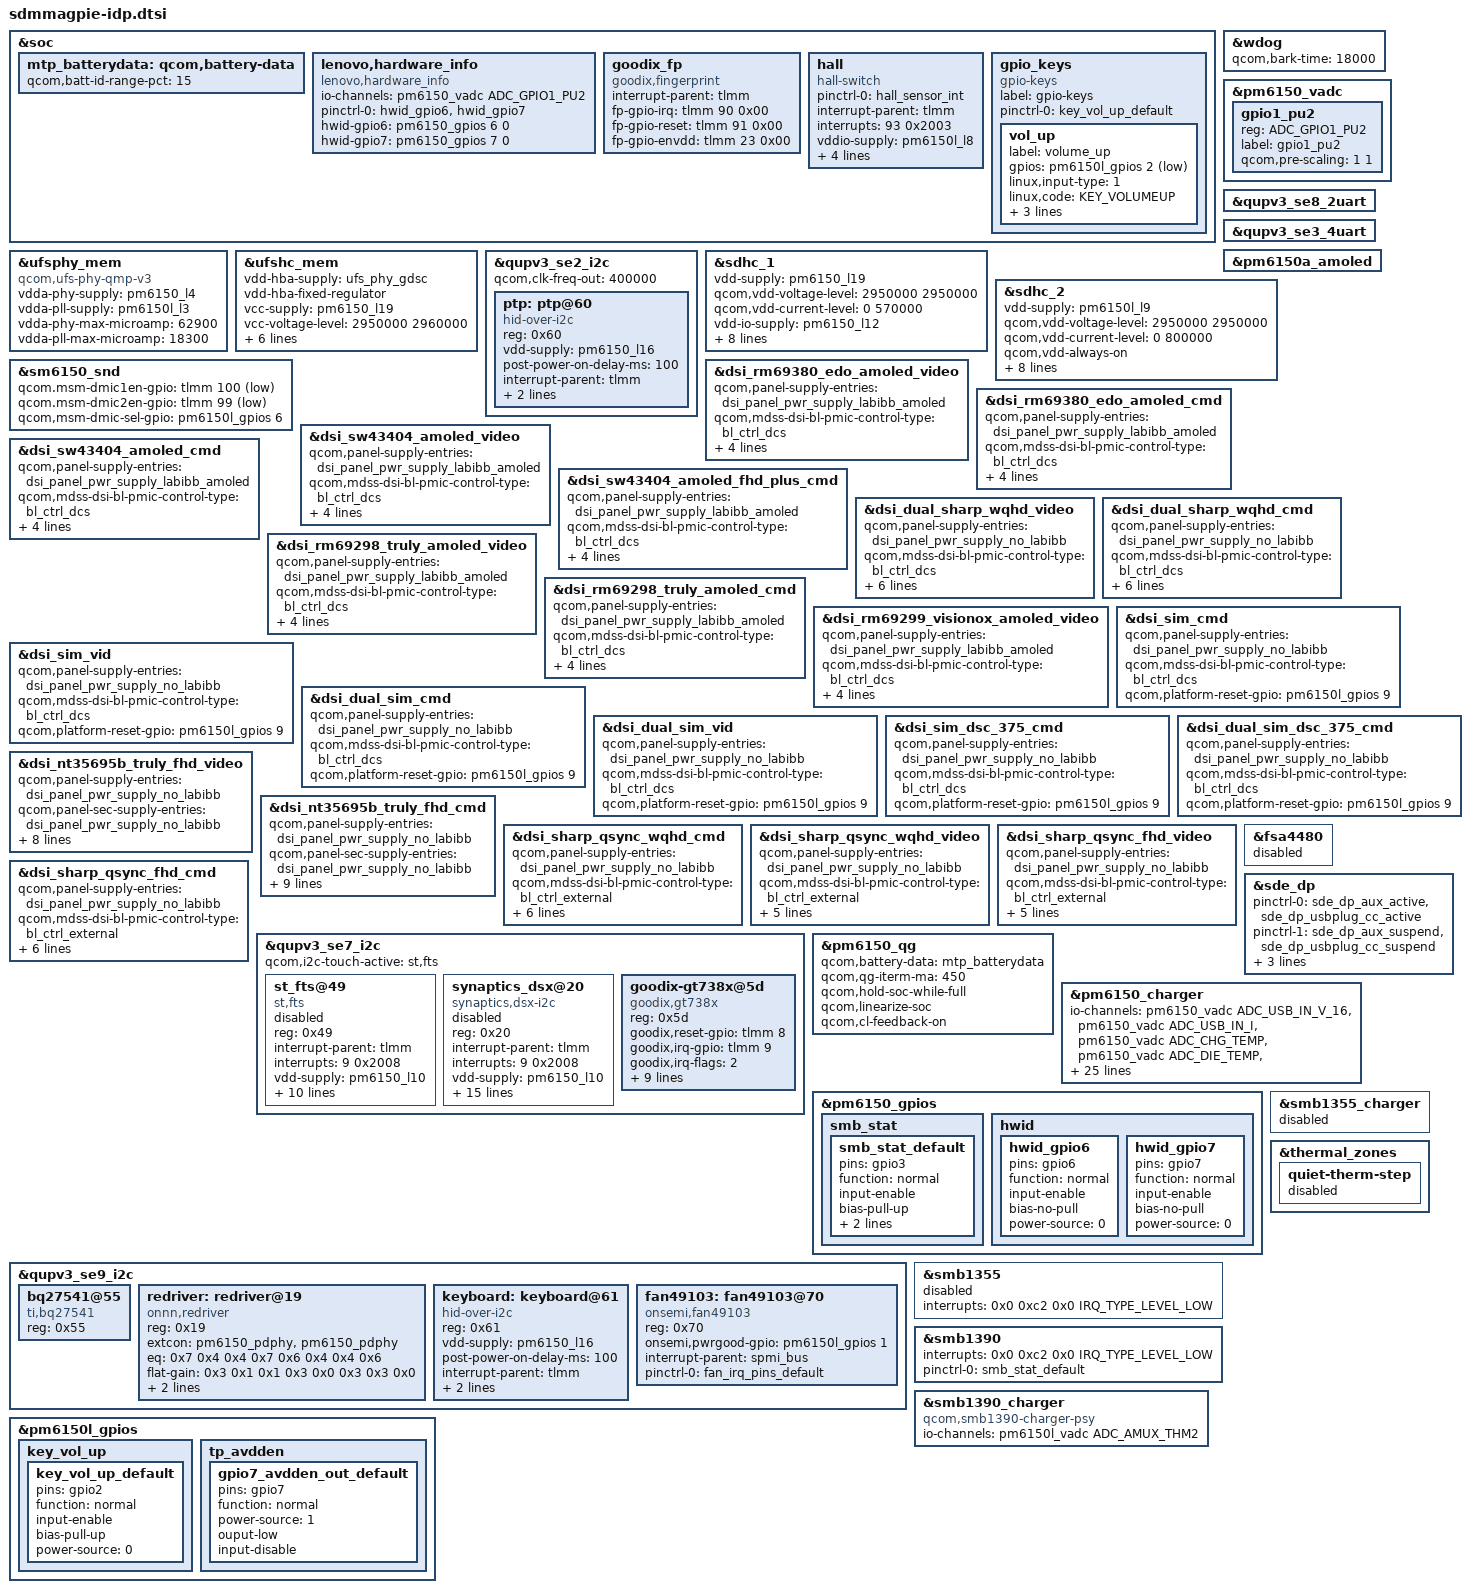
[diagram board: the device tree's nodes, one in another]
/* Copyright (c) 2018-2019, The Linux Foundation. All rights reserved.
 *
 * This program is free software; you can redistribute it and/or modify
 * it under the terms of the GNU General Public License version 2 and
 * only version 2 as published by the Free Software Foundation.
 *
 * This program is distributed in the hope that it will be useful,
 * but WITHOUT ANY WARRANTY; without even the implied warranty of
 * MERCHANTABILITY or FITNESS FOR A PARTICULAR PURPOSE.  See the
 * GNU General Public License for more details.
 */
#include "sdmmagpie-thermal-overlay.dtsi"

#include <dt-bindings/gpio/gpio.h>
#include <dt-bindings/pinctrl/qcom,pmic-gpio.h>
#include <dt-bindings/iio/qcom,spmi-vadc.h>
#include <dt-bindings/input/input.h>
#include "sdmmagpie-sde-display.dtsi"
#include "sdmmagpie-camera-sensor-idp.dtsi"

&soc {
	mtp_batterydata: qcom,battery-data {
		qcom,batt-id-range-pct = <15>;
		#include "qg-batterydata-alium-3600mah.dtsi"
		#include "qg-batterydata-mlp466076-3200mah.dtsi"
	};
	lenovo,hardware_info {
		compatible = "lenovo,hardware_info";
		io-channels = <&pm6150_vadc ADC_GPIO1_PU2>;
		io-channel-names = "hwid_gpio1";
		pinctrl-names = "default";
		pinctrl-0 = <&hwid_gpio6 &hwid_gpio7>;
		hwid-gpio6 = <&pm6150_gpios 6 0>;
		hwid-gpio7 = <&pm6150_gpios 7 0>;
		status = "ok";
	};
	goodix_fp {
			compatible = "goodix,fingerprint";
			interrupt-parent = <&tlmm>;
			fp-gpio-irq = <&tlmm 90 0x00>;
			fp-gpio-reset = <&tlmm 91 0x00>;
			fp-gpio-envdd = <&tlmm 23 0x00>;
			status = "okay";
	};
	hall {
		compatible = "hall-switch";
		pinctrl-names = "default";
		pinctrl-0 = <&hall_sensor_int>;
		interrupt-parent = <&tlmm>;
		interrupts = <93 0x2003>;
		vddio-supply = <&pm6150l_l8>;
		linux,gpio-int = <&tlmm 93 0x1>;
		linux,wakeup;
		linux,min-uv = <1650000>;
		linux,max-uv = <3300000>;
	};
};
&wdog {
	qcom,bark-time = <18000>;
};

&pm6150_vadc {
	gpio1_pu2 {
		reg = <ADC_GPIO1_PU2>;
		label = "gpio1_pu2";
		qcom,pre-scaling = <1 1>;
	};
};

&qupv3_se8_2uart {
	status = "ok";
};

&qupv3_se3_4uart {
	status = "ok";
};

&pm6150a_amoled {
	status = "ok";
};

&ufsphy_mem {
	compatible = "qcom,ufs-phy-qmp-v3";

	vdda-phy-supply = <&pm6150_l4>; /* 0.88v */
	vdda-pll-supply = <&pm6150l_l3>; /* 1.2v */
	vdda-phy-max-microamp = <62900>;
	vdda-pll-max-microamp = <18300>;

	status = "ok";
};

&ufshc_mem {
	vdd-hba-supply = <&ufs_phy_gdsc>;
	vdd-hba-fixed-regulator;
	vcc-supply = <&pm6150_l19>;
	vcc-voltage-level = <2950000 2960000>;
	vccq2-supply = <&pm6150_l12>;
	vccq2-voltage-level = <1750000 1950000>;
	vcc-max-microamp = <600000>;
	vccq2-max-microamp = <600000>;

	qcom,vddp-ref-clk-supply = <&pm6150l_l3>;
	qcom,vddp-ref-clk-max-microamp = <100>;

	status = "ok";
};

&qupv3_se2_i2c {
	status = "ok";
	qcom,clk-freq-out = <400000>;
	 ptp: ptp@60{
		       compatible = "hid-over-i2c";
		       reg = <0x60>;
		    /* pinctrl-names = "default";
		       pinctrl-0 = <&cpu1_dig_irq_l &cpu1_dig_pdct_l>;*/
	           vdd-supply = <&pm6150_l16>;
	           post-power-on-delay-ms = <100>;
	           interrupt-parent = <&tlmm>;
	           interrupts = <4 0x2002>;
	           hid-descr-addr = <0x0001>;
		    };
	/*
	nq@28 {
		compatible = "qcom,nq-nci";
		reg = <0x28>;
		qcom,nq-irq = <&tlmm 37 0x00>;
		qcom,nq-ven = <&tlmm 12 0x00>;
		qcom,nq-firm = <&tlmm 36 0x00>;
		qcom,nq-clkreq = <&tlmm 31 0x00>;
		qcom,nq-esepwr = <&tlmm 94 0x00>;
		interrupt-parent = <&tlmm>;
		interrupts = <37 0>;
		interrupt-names = "nfc_irq";
		pinctrl-names = "nfc_active", "nfc_suspend";
		pinctrl-0 = <&nfc_int_active &nfc_enable_active
				&nfc_clk_req_active>;
		pinctrl-1 = <&nfc_int_suspend &nfc_enable_suspend
				&nfc_clk_req_suspend>;
	};*/
};

&sdhc_1 {
	vdd-supply = <&pm6150_l19>;
	qcom,vdd-voltage-level = <2950000 2950000>;
	qcom,vdd-current-level = <0 570000>;

	vdd-io-supply = <&pm6150_l12>;
	qcom,vdd-io-always-on;
	qcom,vdd-io-lpm-sup;
	qcom,vdd-io-voltage-level = <1800000 1800000>;
	qcom,vdd-io-current-level = <0 325000>;

	pinctrl-names = "active", "sleep";
	pinctrl-0 = <&sdc1_clk_on &sdc1_cmd_on &sdc1_data_on &sdc1_rclk_on>;
	pinctrl-1 = <&sdc1_clk_off &sdc1_cmd_off &sdc1_data_off &sdc1_rclk_off>;

	status = "ok";
};

&sdhc_2 {
	vdd-supply = <&pm6150l_l9>;
	qcom,vdd-voltage-level = <2950000 2950000>;
	qcom,vdd-current-level = <0 800000>;
	qcom,vdd-always-on;

	vdd-io-supply = <&pm6150l_l6>;
	qcom,vdd-io-voltage-level = <1800000 2950000>;
	qcom,vdd-io-current-level = <0 22000>;

	pinctrl-names = "active", "sleep";
	pinctrl-0 = <&sdc2_clk_on  &sdc2_cmd_on &sdc2_data_on &sdc2_cd_on>;
	pinctrl-1 = <&sdc2_clk_off &sdc2_cmd_off &sdc2_data_off &sdc2_cd_off>;

	cd-gpios = <&tlmm 69 GPIO_ACTIVE_HIGH>;

	status = "ok";
};

&sm6150_snd {
	qcom.msm-dmic1en-gpio=<&tlmm 100 1>;
	qcom.msm-dmic2en-gpio=<&tlmm 99 1>;
	qcom,msm-dmic-sel-gpio = <&pm6150l_gpios 6 0>;
};

&dsi_rm69380_edo_amoled_video {
	qcom,panel-supply-entries = <&dsi_panel_pwr_supply_labibb_amoled>;
	qcom,mdss-dsi-bl-pmic-control-type = "bl_ctrl_dcs";
	qcom,mdss-dsi-bl-min-level = <1>;
	qcom,mdss-dsi-bl-max-level = <2047>;	// 11bit
	qcom,platform-te-gpio = <&tlmm 10 0>;
	qcom,platform-reset-gpio = <&pm6150l_gpios 9 0>;
};

&dsi_rm69380_edo_amoled_cmd {
	qcom,panel-supply-entries = <&dsi_panel_pwr_supply_labibb_amoled>;
	qcom,mdss-dsi-bl-pmic-control-type = "bl_ctrl_dcs";
	qcom,mdss-dsi-bl-min-level = <1>;
	qcom,mdss-dsi-bl-max-level = <2047>;	// 11bit
	qcom,platform-te-gpio = <&tlmm 10 0>;
	qcom,platform-reset-gpio = <&pm6150l_gpios 9 0>;
};
&dsi_sw43404_amoled_video {
	qcom,panel-supply-entries = <&dsi_panel_pwr_supply_labibb_amoled>;
	qcom,mdss-dsi-bl-pmic-control-type = "bl_ctrl_dcs";
	qcom,mdss-dsi-bl-min-level = <1>;
	qcom,mdss-dsi-bl-max-level = <1023>;
	qcom,platform-te-gpio = <&tlmm 10 0>;
	qcom,platform-reset-gpio = <&pm6150l_gpios 9 0>;
};

&dsi_sw43404_amoled_cmd {
	qcom,panel-supply-entries = <&dsi_panel_pwr_supply_labibb_amoled>;
	qcom,mdss-dsi-bl-pmic-control-type = "bl_ctrl_dcs";
	qcom,mdss-dsi-bl-min-level = <1>;
	qcom,mdss-dsi-bl-max-level = <1023>;
	qcom,platform-te-gpio = <&tlmm 10 0>;
	qcom,platform-reset-gpio = <&pm6150l_gpios 9 0>;
};

&dsi_sw43404_amoled_fhd_plus_cmd {
	qcom,panel-supply-entries = <&dsi_panel_pwr_supply_labibb_amoled>;
	qcom,mdss-dsi-bl-pmic-control-type = "bl_ctrl_dcs";
	qcom,mdss-dsi-bl-min-level = <1>;
	qcom,mdss-dsi-bl-max-level = <1023>;
	qcom,platform-te-gpio = <&tlmm 10 0>;
	qcom,platform-reset-gpio = <&pm6150l_gpios 9 0>;
};

&dsi_dual_sharp_wqhd_video {
	qcom,panel-supply-entries = <&dsi_panel_pwr_supply_no_labibb>;
	qcom,mdss-dsi-bl-pmic-control-type = "bl_ctrl_dcs";
	qcom,mdss-dsi-bl-min-level = <1>;
	qcom,mdss-dsi-bl-max-level = <4095>;
	qcom,platform-te-gpio = <&tlmm 10 0>;
	qcom,platform-reset-gpio = <&pm6150l_gpios 9 0>;
	qcom,platform-en-gpio = <&pm6150l_gpios 4 0>;
	qcom,platform-bklight-en-gpio = <&pm6150l_gpios 5 0>;
};

&dsi_dual_sharp_wqhd_cmd {
	qcom,panel-supply-entries = <&dsi_panel_pwr_supply_no_labibb>;
	qcom,mdss-dsi-bl-pmic-control-type = "bl_ctrl_dcs";
	qcom,mdss-dsi-bl-min-level = <1>;
	qcom,mdss-dsi-bl-max-level = <4095>;
	qcom,platform-te-gpio = <&tlmm 10 0>;
	qcom,platform-reset-gpio = <&pm6150l_gpios 9 0>;
	qcom,platform-en-gpio = <&pm6150l_gpios 4 0>;
	qcom,platform-bklight-en-gpio = <&pm6150l_gpios 5 0>;
};

&dsi_rm69298_truly_amoled_video {
	qcom,panel-supply-entries = <&dsi_panel_pwr_supply_labibb_amoled>;
	qcom,mdss-dsi-bl-pmic-control-type = "bl_ctrl_dcs";
	qcom,mdss-dsi-bl-min-level = <1>;
	qcom,mdss-dsi-bl-max-level = <255>;
	qcom,platform-te-gpio = <&tlmm 10 0>;
	qcom,platform-reset-gpio = <&pm6150l_gpios 9 0>;
};

&dsi_rm69298_truly_amoled_cmd {
	qcom,panel-supply-entries = <&dsi_panel_pwr_supply_labibb_amoled>;
	qcom,mdss-dsi-bl-pmic-control-type = "bl_ctrl_dcs";
	qcom,mdss-dsi-bl-min-level = <1>;
	qcom,mdss-dsi-bl-max-level = <255>;
	qcom,platform-te-gpio = <&tlmm 10 0>;
	qcom,platform-reset-gpio = <&pm6150l_gpios 9 0>;
};

&dsi_rm69299_visionox_amoled_video {
	qcom,panel-supply-entries = <&dsi_panel_pwr_supply_labibb_amoled>;
	qcom,mdss-dsi-bl-pmic-control-type = "bl_ctrl_dcs";
	qcom,mdss-dsi-bl-min-level = <1>;
	qcom,mdss-dsi-bl-max-level = <255>;
	qcom,platform-te-gpio = <&tlmm 10 0>;
	qcom,platform-reset-gpio = <&pm6150l_gpios 9 0>;
};

&dsi_sim_cmd {
	qcom,panel-supply-entries = <&dsi_panel_pwr_supply_no_labibb>;
	qcom,mdss-dsi-bl-pmic-control-type = "bl_ctrl_dcs";
	qcom,platform-reset-gpio = <&pm6150l_gpios 9 0>;
};

&dsi_sim_vid {
	qcom,panel-supply-entries = <&dsi_panel_pwr_supply_no_labibb>;
	qcom,mdss-dsi-bl-pmic-control-type = "bl_ctrl_dcs";
	qcom,platform-reset-gpio = <&pm6150l_gpios 9 0>;
};

&dsi_dual_sim_cmd {
	qcom,panel-supply-entries = <&dsi_panel_pwr_supply_no_labibb>;
	qcom,mdss-dsi-bl-pmic-control-type = "bl_ctrl_dcs";
	qcom,platform-reset-gpio = <&pm6150l_gpios 9 0>;
};

&dsi_dual_sim_vid {
	qcom,panel-supply-entries = <&dsi_panel_pwr_supply_no_labibb>;
	qcom,mdss-dsi-bl-pmic-control-type = "bl_ctrl_dcs";
	qcom,platform-reset-gpio = <&pm6150l_gpios 9 0>;
};

&dsi_sim_dsc_375_cmd {
	qcom,panel-supply-entries = <&dsi_panel_pwr_supply_no_labibb>;
	qcom,mdss-dsi-bl-pmic-control-type = "bl_ctrl_dcs";
	qcom,platform-reset-gpio = <&pm6150l_gpios 9 0>;
};

&dsi_dual_sim_dsc_375_cmd {
	qcom,panel-supply-entries = <&dsi_panel_pwr_supply_no_labibb>;
	qcom,mdss-dsi-bl-pmic-control-type = "bl_ctrl_dcs";
	qcom,platform-reset-gpio = <&pm6150l_gpios 9 0>;
};

&dsi_nt35695b_truly_fhd_video {
	qcom,panel-supply-entries = <&dsi_panel_pwr_supply_no_labibb>;
	qcom,panel-sec-supply-entries = <&dsi_panel_pwr_supply_no_labibb>;
	qcom,mdss-dsi-bl-pmic-control-type = "bl_ctrl_dcs";
	qcom,mdss-dsi-sec-bl-pmic-control-type = "bl_ctrl_dcs";
	qcom,platform-reset-gpio = <&pm6150l_gpios 11 0>;
	qcom,platform-sec-reset-gpio = <&pm6150l_gpios 11 0>;
	qcom,platform-en-gpio = <&pm6150l_gpios 4 0>;
	qcom,platform-bklight-en-gpio = <&pm6150l_gpios 5 0>;
};

&dsi_nt35695b_truly_fhd_cmd {
	qcom,panel-supply-entries = <&dsi_panel_pwr_supply_no_labibb>;
	qcom,panel-sec-supply-entries = <&dsi_panel_pwr_supply_no_labibb>;
	qcom,mdss-dsi-bl-pmic-control-type = "bl_ctrl_dcs";
	qcom,mdss-dsi-sec-bl-pmic-control-type = "bl_ctrl_dcs";
	qcom,platform-reset-gpio = <&pm6150l_gpios 11 0>;
	qcom,platform-sec-reset-gpio = <&pm6150l_gpios 11 0>;
	qcom,platform-en-gpio = <&pm6150l_gpios 4 0>;
	qcom,platform-bklight-en-gpio = <&pm6150l_gpios 5 0>;
	qcom,platform-te-gpio = <&tlmm 11 0>;
};

&dsi_sharp_qsync_wqhd_cmd {
	qcom,panel-supply-entries = <&dsi_panel_pwr_supply_no_labibb>;
	qcom,mdss-dsi-bl-pmic-control-type = "bl_ctrl_external";
	qcom,mdss-dsi-bl-min-level = <1>;
	qcom,mdss-dsi-bl-max-level = <4095>;
	qcom,platform-te-gpio = <&tlmm 10 0>;
	qcom,platform-reset-gpio = <&pm6150l_gpios 9 0>;
	qcom,platform-en-gpio = <&pm6150l_gpios 4 0>;
	qcom,platform-bklight-en-gpio = <&pm6150l_gpios 5 0>;
};

&dsi_sharp_qsync_wqhd_video {
	qcom,panel-supply-entries = <&dsi_panel_pwr_supply_no_labibb>;
	qcom,mdss-dsi-bl-pmic-control-type = "bl_ctrl_external";
	qcom,mdss-dsi-bl-min-level = <1>;
	qcom,mdss-dsi-bl-max-level = <4095>;
	qcom,platform-reset-gpio = <&pm6150l_gpios 9 0>;
	qcom,platform-en-gpio = <&pm6150l_gpios 4 0>;
	qcom,platform-bklight-en-gpio = <&pm6150l_gpios 5 0>;
};

&dsi_sharp_qsync_fhd_video {
	qcom,panel-supply-entries = <&dsi_panel_pwr_supply_no_labibb>;
	qcom,mdss-dsi-bl-pmic-control-type = "bl_ctrl_external";
	qcom,mdss-dsi-bl-min-level = <1>;
	qcom,mdss-dsi-bl-max-level = <4095>;
	qcom,platform-reset-gpio = <&pm6150l_gpios 9 0>;
	qcom,platform-en-gpio = <&pm6150l_gpios 4 0>;
	qcom,platform-bklight-en-gpio = <&pm6150l_gpios 5 0>;
};

&dsi_sharp_qsync_fhd_cmd {
	qcom,panel-supply-entries = <&dsi_panel_pwr_supply_no_labibb>;
	qcom,mdss-dsi-bl-pmic-control-type = "bl_ctrl_external";
	qcom,mdss-dsi-bl-min-level = <1>;
	qcom,mdss-dsi-bl-max-level = <4095>;
	qcom,platform-te-gpio = <&tlmm 10 0>;
	qcom,platform-reset-gpio = <&pm6150l_gpios 9 0>;
	qcom,platform-en-gpio = <&pm6150l_gpios 4 0>;
	qcom,platform-bklight-en-gpio = <&pm6150l_gpios 5 0>;
};
&fsa4480 {
	status = "disabled";
};
&sde_dp {
/*  	for gpio switch*/

	pinctrl-names = "mdss_dp_active", "mdss_dp_sleep";
	pinctrl-0 = <&sde_dp_aux_active &sde_dp_usbplug_cc_active>;
	pinctrl-1 = <&sde_dp_aux_suspend &sde_dp_usbplug_cc_suspend>;
	qcom,aux-en-gpio = <&tlmm 25 0>;
	qcom,aux-sel-gpio = <&tlmm 33 0>;
	qcom,dp-gpio-aux-switch;

	//qcom,dp-aux-switch = <&redriver>;
};

&qupv3_se7_i2c {
	qcom,i2c-touch-active="st,fts";
	status = "ok";

	st_fts@49 {
		compatible = "st,fts";
		reg = <0x49>;
		interrupt-parent = <&tlmm>;
		interrupts = <9 0x2008>;
		vdd-supply = <&pm6150_l10>;
		avdd-supply = <&pm6150l_l7>;
		pinctrl-names = "pmx_ts_active", "pmx_ts_suspend",
					"pmx_ts_release";
		pinctrl-0 = <&ts_active>;
		pinctrl-1 = <&ts_int_suspend &ts_reset_suspend>;
		pinctrl-2 = <&ts_release>;
		st,irq-gpio = <&tlmm 9 0x2008>;
		st,reset-gpio = <&tlmm 8 0x00>;
		st,regulator_dvdd = "vdd";
		st,regulator_avdd = "avdd";
		st,x-flip;
		st,y-flip;
		status = "disabled";
	};

	synaptics_dsx@20 {
		compatible = "synaptics,dsx-i2c";
		reg = <0x20>;
		interrupt-parent = <&tlmm>;
		interrupts = <9 0x2008>;
		vdd-supply = <&pm6150_l10>;
		avdd-supply = <&pm6150l_l7>;
		pinctrl-names = "pmx_ts_active","pmx_ts_suspend",
					"pmx_ts_release";
		pinctrl-0 = <&ts_active>;
		pinctrl-1 = <&ts_int_suspend &ts_reset_suspend>;
		pinctrl-2 = <&ts_release>;
		synaptics,pwr-reg-name = "avdd";
		synaptics,bus-reg-name = "vdd";
		synaptics,ub-i2c-addr = <0x20>;
		synaptics,max-y-for-2d = <2159>;
		synaptics,irq-gpio = <&tlmm 9 0x2008>;
		synaptics,reset-gpio = <&tlmm 8 0x0>;
		synaptics,irq-on-state = <0>;
		synaptics,power-delay-ms = <200>;
		synaptics,reset-delay-ms = <200>;
		synaptics,reset-on-state = <0>;
		synaptics,reset-active-ms = <20>;
		status = "disabled";
	};
	goodix-gt738x@5d {
		compatible = "goodix,gt738x";
		reg = <0x5d>;
		goodix,reset-gpio = <&tlmm 8 0x0>;
		goodix,irq-gpio = <&tlmm 9 0x2008>;
		goodix,irq-flags = <2>; /* 1:trigger rising, 2:trigger falling;*/
		goodix,panel-max-x = <2560>;
		goodix,panel-max-y = <1600>;
		goodix,panel-max-w = <2368>;
		goodix,avdd-name ="avdd";
		goodix,avdd-en-gpio =<&pm6150l_gpios 7 0>;
		avdd-supply = <&pm6150l_l7>;
		pinctrl-names = "pmx_ts_active", "pmx_ts_suspend", "pmx_ts_release","avddengpio";
		pinctrl-0 = <&ts_active &gpio7_avdden_out_default>;
		pinctrl-1 = <&ts_int_suspend &ts_reset_suspend>;
		pinctrl-2 = <&ts_release>;
	};
};

&pm6150_qg {
	qcom,battery-data = <&mtp_batterydata>;
	qcom,qg-iterm-ma = <450>;
	qcom,hold-soc-while-full;
	qcom,linearize-soc;
	qcom,cl-feedback-on;
};

&pm6150_charger {
	io-channels = <&pm6150_vadc ADC_USB_IN_V_16>,
		      <&pm6150_vadc ADC_USB_IN_I>,
		      <&pm6150_vadc ADC_CHG_TEMP>,
		      <&pm6150_vadc ADC_DIE_TEMP>,
		      <&pm6150l_vadc ADC_AMUX_THM1_PU2>,
		      <&pm6150_vadc ADC_SBUx>,
		      <&pm6150_vadc ADC_VPH_PWR>;
	io-channel-names = "usb_in_voltage",
			   "usb_in_current",
			   "chg_temp",
			   "die_temp",
			   "conn_temp",
			   "sbux_res",
			   "vph_voltage";
	qcom,battery-data = <&mtp_batterydata>;
	/*qcom,auto-recharge-soc = <95>;*/
	qcom,auto-recharge-vbat-mv = <4330>;
	#qcom,step-charging-enable;
	qcom,sw-jeita-enable;
	#qcom,fcc-stepping-enable;
	#qcom,suspend-input-on-debug-batt;
	qcom,sec-charger-config = <1>;
	qcom,thermal-mitigation = <4200000 3500000 3000000
			2500000 2000000 1500000 1000000 500000>;
	dpdm-supply = <&qusb_phy0>;
	qcom,charger-temp-max = <800>;
	qcom,smb-temp-max = <800>;
	qcom,chg-term-src = <1>;
	qcom,chg-term-current-ma = <(-400)>;
	qcom,usb-icl-ua = <2000000>;
	qcom,float-option = <2>;
	qcom,boost_en=<&pm6150l_gpios 11 0>;
	pinctrl-names = "default";
	pinctrl-0 = <&pogo_gpio>;
	qcom,pogo_det-gpio=<&tlmm 94 0>;
	qcom,typec_det-gpio=<&tlmm 66 0>;
	qcom,pogo_en-gpio=<&tlmm 65 0>;
	qcom,typec_en-gpio=<&tlmm 74 0>;
};

&pm6150_gpios {
	smb_stat {
		smb_stat_default: smb_stat_default {
			pins = "gpio3";
			function = "normal";
			input-enable;
			bias-pull-up;
			qcom,pull-up-strength = <PMIC_GPIO_PULL_UP_30>;
			power-source = <0>;
		};
	};

	hwid {
		hwid_gpio6: hwid_gpio6 {
			pins = "gpio6";
			function = "normal";
			input-enable;
			bias-no-pull;
			power-source = <0>;
		};

		hwid_gpio7: hwid_gpio7 {
			pins = "gpio7";
			function = "normal";
			input-enable;
			bias-no-pull;
			power-source = <0>;
		};
	};
};

&qupv3_se9_i2c {
	status = "ok";
	#include "smb1390.dtsi"
	#include "smb1355.dtsi"
	bq27541@55 {
		compatible = "ti,bq27541";
		reg = <0x55>;
	};
	redriver:redriver@19 {
                compatible = "onnn,redriver";
                reg = <0x19>;
                extcon = <&pm6150_pdphy>, <&pm6150_pdphy>;
		eq = /bits/ 8 <
				/* Parameters for USB */
				0x7 0x4 0x4 0x7
				/* Parameters for DP */
				0x6 0x4 0x4 0x6>;
		flat-gain = /bits/ 8 <
				/* Parameters for USB */
				0x3 0x1 0x1 0x3
				/* Parameters for DP */
				0x0 0x3 0x3 0x0>;
		output-comp = /bits/ 8 <
				/* Parameters for USB */
				0x3 0x3 0x3 0x3
				/* Parameters for DP */
				0x3 0x3 0x3 0x3>;
		loss-match = /bits/ 8 <
				/* Parameters for USB */
				0x1 0x3 0x3 0x1
				/* Parameters for DP */
				0x2 0x2 0x2 0x2>;
        };
	keyboard:  keyboard@61 {
			      compatible = "hid-over-i2c";
			      reg = <0x61>;
		          vdd-supply = <&pm6150_l16>;
		          post-power-on-delay-ms = <100>;
		          interrupt-parent = <&tlmm>;
		          interrupts = <5 0x2002>;
		          hid-descr-addr = <0x0001>;
		         };

	fan49103:fan49103@70 {
		compatible = "onsemi,fan49103";
		reg = <0x70>;
		onsemi,pwrgood-gpio = <&pm6150l_gpios 1 0>;
		interrupt-parent = <&spmi_bus>;
		pinctrl-names = "default";
		pinctrl-0 = <&fan_irq_pins_default>;
	};
};

&smb1355 {
	/delete-property/ interrupts;
	interrupts = <0x0 0xc2 0x0 IRQ_TYPE_LEVEL_LOW>;
	status = "disabled";
};

&smb1355_charger {
	status = "disabled";
};

&smb1390 {
	/delete-property/ interrupts;
	interrupts = <0x0 0xc2 0x0 IRQ_TYPE_LEVEL_LOW>;
	pinctrl-names = "default";
	pinctrl-0 = <&smb_stat_default>;
	status = "ok";
};

&smb1390_charger {
	compatible = "qcom,smb1390-charger-psy";
	io-channels = <&pm6150l_vadc ADC_AMUX_THM2>;
	io-channel-names = "cp_die_temp";
	status = "ok";
};

&pm6150l_gpios {
	key_vol_up {
		key_vol_up_default: key_vol_up_default {
			pins = "gpio2";
			function = "normal";
			input-enable;
			bias-pull-up;
			power-source = <0>;
		};
	};
	tp_avdden {
		gpio7_avdden_out_default:gpio7_avdden_out_default{
			pins = "gpio7";
			function = "normal";
			power-source = <1>;
			ouput-low;
			input-disable;
			    };
			};
		};

&soc {
	gpio_keys {
		compatible = "gpio-keys";
		label = "gpio-keys";

		pinctrl-names = "default";
		pinctrl-0 = <&key_vol_up_default>;

		vol_up {
			label = "volume_up";
			gpios = <&pm6150l_gpios 2 GPIO_ACTIVE_LOW>;
			linux,input-type = <1>;
			linux,code = <KEY_VOLUMEUP>;
			linux,can-disable;
			debounce-interval = <15>;
			gpio-key,wakeup;
		};
	};
};

&thermal_zones {
	quiet-therm-step {
		status = "disabled";
	};
};
